# PIC32MX274F256B device description
Architecture: MIPS; Family: PIC32MX; Series: PIC32MX
Registers are 32-bit, read-write, no defined reset value unless marked. A register's access mark holds for its fields unless they carry their own. Offsets are from the block's base; [hi:lo] are bit positions; {n}, {i} and the like mark numbered series; 'fields as' and 'values as' point back to an identical list.

## ADC
Instances: ADC 0x1f809000 in periph0
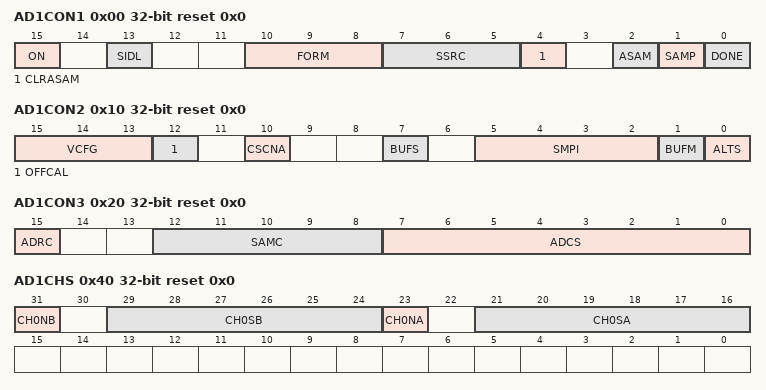
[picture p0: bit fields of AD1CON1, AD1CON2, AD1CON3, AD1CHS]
0x00 AD1CON1 reset 0x0 — ADC Control Register 1
  [15] ON — ADC Operating Mode bit
    1=ADC module is operating; 0=ADC module is not operating
  [13] SIDL — Stop in Idle Mode bit
    1=Discontinue module operation when device enters Idle mode; 0=Continue module operation in Idle mode
  [10:8] FORM — Data Output Format bits
    3=Signed Fractional 16-bit; 2=Fractional 16-bit; 1=Signed Integer 16-bit; 0=Integer 16-bit; 7=Signed Fractional 32-bit; 6=Fractional 32-bit; 5=Signed Integer 32-bit; 4=Integer 32-bit
  [7:5] SSRC — Conversion Trigger Source Select bits
    7=Internal counter ends sampling and starts conversion (auto convert); 3=CTMU ends sampling and starts conversion; 2=Timer 3 period match ends sampling and starts conversion; 1=Active transition on INT0 pin ends sampling and starts conversion; 0=Clearing SAMP bit ends sampling and starts conversion
  [4] CLRASAM — Stop Conversion Sequence bit (when the first ADC interrupt is generated)
    1=Stop conversions when the first ADC interrupt is generated. Hardware clears the ASAM bit when the ADC interrupt is generated; 0=Normal operation, buffer contents will be overwritten by the next conversion sequence
  [2] ASAM — ADC Sample Auto-Start bit
    1=Sampling begins immediately after last conversion completes; SAMP bit is automatically set; 0=Sampling begins when SAMP bit is set
  [1] SAMP — ADC Sample Enable bit
    1=The ADC sample and hold amplifier is sampling; 0=The ADC sample/hold amplifier is holding
  [0] DONE — Analog-to-Digital Conversion Status bit
    1=Analog-to-digital conversion is done; 0=Analog-to-digital conversion is not done or has not started
0x10 AD1CON2 reset 0x0 — ADC Control Register 2
  [15:13] VCFG — Voltage Reference Configuration bits
    0=VREFH is AVDD and VREFL is AVSS; 1=VREFH is External VREF+ pin and VREFL is AVSS; 2=VREFH is AVDD and VREFL is External VREF- pin; 3=VREFH is External VREF+ pin and VREFL is External VREF- pin; {v}=VREFH is AVDD and VREFL is AVSS (v=4..7)
  [12] OFFCAL — Input Offset Calibration Mode Select bit
    1=Enable Offset Calibration mode; 0=Disable Offset Calibration mode
  [10] CSCNA — Input Scan Select bit
    1=Scan inputs; 0=Do not scan inputs
  [7] BUFS — Buffer Fill Status bit
    1=ADC is currently filling buffer 0x8-0xF, user should access data in 0x0-0x7; 0=ADC is currently filling buffer 0x0-0x7, user should access data in 0x8-0xF
  [5:2] SMPI — Sample/Convert Sequences Per Interrupt Selection bits
    {v}=Interrupts at the completion of conversion for each {v+1}th sample/convert sequence (v=3..15); 2=Interrupts at the completion of conversion for each 3rd sample/convert sequence; 1=Interrupts at the completion of conversion for each 2nd sample/convert sequence; 0=Interrupts at the completion of conversion for each sample/convert sequence
  [1] BUFM — ADC Result Buffer Mode Select bit
    1=Buffer configured as two 8-word buffers; 0=Buffer configured as one 16-word buffer ADC1BUFF-ADC1BUF0
  [0] ALTS — Alternate Input Sample Mode Select bit
    1=Uses Sample A input multiplexer settings for first sample then alternates between Sample B and Sample A input multiplexer settings for all subsequent samples; 0=Always use Sample A input multiplexer settings
0x20 AD1CON3 reset 0x0 — ADC Control Register 3
  [15] ADRC — ADC Conversion Clock Source bit
    1=Clock derived from FRC; 0=Clock derived from Peripheral Bus Clock (PBCLK)
  [12:8] SAMC — Auto-Sample Time bits
    {v}={v} TAD (v=1..31)
  [7:0] ADCS — ADC Conversion Clock Select bits
    255=512 TPB; 254=510 TPB; 253=508 TPB; 252=506 TPB; 251=504 TPB; 250=502 TPB; 249=500 TPB; 248=498 TPB; 247=496 TPB; 246=494 TPB; 245=492 TPB; 244=490 TPB; 243=488 TPB; 242=486 TPB; 241=484 TPB; 240=482 TPB; 239=480 TPB; 238=478 TPB; 237=476 TPB; 236=474 TPB; 235=472 TPB; 234=470 TPB; 233=468 TPB; 232=466 TPB; 231=464 TPB; 230=462 TPB; 229=460 TPB; 228=458 TPB; 227=456 TPB; 226=454 TPB; 225=452 TPB; 224=450 TPB; 223=448 TPB; 222=446 TPB; 221=444 TPB; 220=442 TPB; 219=440 TPB; 218=438 TPB; 217=436 TPB; 216=434 TPB; 215=432 TPB; 214=430 TPB; 213=428 TPB; 212=426 TPB; 211=424 TPB; 210=422 TPB; 209=420 TPB; 208=418 TPB; 207=416 TPB; 206=414 TPB; 205=412 TPB; 204=410 TPB; 203=408 TPB; 202=406 TPB; 201=404 TPB; 200=402 TPB; 199=400 TPB; 198=398 TPB; 197=396 TPB; 196=394 TPB; 195=392 TPB; 194=390 TPB; 193=388 TPB; 192=386 TPB; 191=384 TPB; 190=382 TPB; 189=380 TPB; 188=378 TPB; 187=376 TPB; 186=374 TPB; 185=372 TPB; 184=370 TPB; 183=368 TPB; 182=366 TPB; 181=364 TPB; 180=362 TPB; 179=360 TPB; 178=358 TPB; 177=356 TPB; 176=354 TPB; 175=352 TPB; 174=350 TPB; 173=348 TPB; 172=346 TPB; 171=344 TPB; 170=342 TPB; 169=340 TPB; 168=338 TPB; 167=336 TPB; 166=334 TPB; 165=332 TPB; 164=330 TPB; 163=328 TPB; 162=326 TPB; 161=324 TPB; 160=322 TPB; 159=320 TPB; 158=318 TPB; 157=316 TPB; 156=314 TPB; 155=312 TPB; 154=310 TPB; 153=308 TPB; 152=306 TPB; 151=304 TPB; 150=302 TPB; 149=300 TPB; 148=298 TPB; 147=296 TPB; 146=294 TPB; 145=292 TPB; 144=290 TPB; 143=288 TPB; 142=286 TPB; 141=284 TPB; 140=282 TPB; 139=280 TPB; 138=278 TPB; 137=276 TPB; 136=274 TPB; 135=272 TPB; 134=270 TPB; 133=268 TPB; 132=266 TPB; 131=264 TPB; 130=262 TPB; 129=260 TPB; 128=258 TPB; 127=256 TPB; 126=254 TPB; 125=252 TPB; 124=250 TPB; 123=248 TPB; 122=246 TPB; 121=244 TPB; 120=242 TPB; 119=240 TPB; 118=238 TPB; 117=236 TPB; 116=234 TPB; 115=232 TPB; 114=230 TPB; 113=228 TPB; 112=226 TPB; 111=224 TPB; 110=222 TPB; 109=220 TPB; 108=218 TPB; 107=216 TPB; 106=214 TPB; 105=212 TPB; 104=210 TPB; 103=208 TPB; 102=206 TPB; 101=204 TPB; 100=202 TPB; 99=200 TPB; 98=198 TPB; 97=196 TPB; 96=194 TPB; 95=192 TPB; 94=190 TPB; 93=188 TPB; 92=186 TPB; 91=184 TPB; 90=182 TPB; 89=180 TPB; 88=178 TPB; 87=176 TPB; 86=174 TPB; 85=172 TPB; 84=170 TPB; 83=168 TPB; 82=166 TPB; 81=164 TPB; 80=162 TPB; 79=160 TPB; 78=158 TPB; 77=156 TPB; 76=154 TPB; 75=152 TPB; 74=150 TPB; 73=148 TPB; 72=146 TPB; 71=144 TPB; 70=142 TPB; 69=140 TPB; 68=138 TPB; 67=136 TPB; 66=134 TPB; 65=132 TPB; 64=130 TPB; 63=128 TPB; 62=126 TPB; 61=124 TPB; 60=122 TPB; 59=120 TPB; 58=118 TPB; 57=116 TPB; 56=114 TPB; 55=112 TPB; 54=110 TPB; 53=108 TPB; 52=106 TPB; 51=104 TPB; 50=102 TPB; 49=100 TPB; 48=98 TPB; 47=96 TPB; 46=94 TPB; 45=92 TPB; 44=90 TPB; 43=88 TPB; 42=86 TPB; 41=84 TPB; 40=82 TPB; 39=80 TPB; 38=78 TPB; 37=76 TPB; 36=74 TPB; 35=72 TPB; 34=70 TPB; 33=68 TPB; 32=66 TPB; 31=64 TPB; 30=62 TPB; 29=60 TPB; 28=58 TPB; 27=56 TPB; 26=54 TPB; 25=52 TPB; 24=50 TPB; 23=48 TPB; 22=46 TPB; 21=44 TPB; 20=42 TPB; 19=40 TPB; 18=38 TPB; 17=36 TPB; 16=34 TPB; 15=32 TPB; 14=30 TPB; 13=28 TPB; 12=26 TPB; 11=24 TPB; 10=22 TPB; 9=20 TPB; 8=18 TPB; 7=16 TPB; 6=14 TPB; 5=12 TPB; 4=10 TPB; 3=8 TPB; 2=6 TPB; 1=4 TPB; 0=2 TPB
0x40 AD1CHS reset 0x0 — ADC Input Select Register
  [31] CH0NB — Negative Input Select bit for Sample B
    1=Channel 0 negative input is AN1; 0=Channel 0 negative input is VREFL
  [29:24] CH0SB — Positive Input Select bits for Sample B
    17=VDD_DIV_2 (Channel 0 positive input is VDD/2); 14=IVREF (Channel 0 positive input is IVREF); 13=CTMUT (Channel 0 positive input is CTMU temperature sensor (CTMUT)); 11=AN11 (Channel 0 positive input is AN11); 10=AN10 (Channel 0 positive input is AN10); 9=AN9 (Channel 0 positive input is AN9); {v}=AN{v} (Channel 0 positive input is AN{v}) (v=0..5)
  [23] CH0NA — Negative Input Select bit for Sample A Multiplexer Setting
    1=AN1 (Channel 0 negative input is AN1); 0=VREFL (Channel 0 negative input is VREFL)
  [21:16] CH0SA — Positive Input Select bits for Sample A Multiplexer Setting
    values as CH0SB
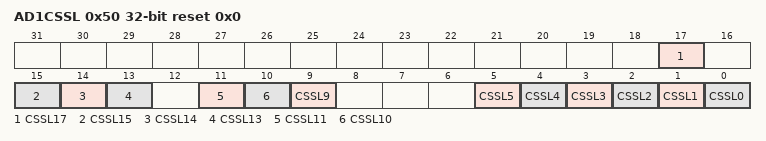
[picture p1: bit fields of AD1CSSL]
0x50 AD1CSSL reset 0x0 — ADC Input Scan Select Register
  [17] CSSL17 — ADC Input Pin Scan Selection bits
    1=Select VDD_DIV_2 for input scan; CSSL17 = VDD_DIV_2; 0=Skip VDD_DIV_2 for input scan; CSSL17 = VDD_DIV_2
  [15] CSSL15 — ADC Input Pin Scan Selection bits
    1=Select AVSS for input scan; CSSL15 = AVSS; 0=Skip AVSS for input scan; CSSL15 = AVSS
  [14] CSSL14 — ADC Input Pin Scan Selection bits
    1=Select IVREF for input scan; CSSL14 = IVREF; 0=Skip IVREF for input scan; CSSL14 = IVREF
  [13] CSSL13 — ADC Input Pin Scan Selection bits
    1=Select CTMUT for input scan; CSSL13 = CTMUT; 0=Skip CTMUT for input scan; CSSL13 = CTMUT
  [11] CSSL11 — ADC Input Pin Scan Selection bits
    1=Select AN11 for input scan; CSSL11 = AN11; 0=Skip AN11 for input scan; CSSL11 = AN11
  [10] CSSL10 — ADC Input Pin Scan Selection bits
    1=Select AN10 for input scan; CSSL10 = AN10; 0=Skip AN10 for input scan; CSSL10 = AN10
  [9] CSSL9 — ADC Input Pin Scan Selection bits
    1=Select AN9 for input scan; CSSL9 = AN9; 0=Skip AN9 for input scan; CSSL9 = AN9
  [n] CSSL{n} (n=0..5) — ADC Input Pin Scan Selection bits
    1=Select AN{n} for input scan; CSSL{n} = AN{n}; 0=Skip AN{n} for input scan; CSSL{n} = AN{n}
{0x70+0x10*i} ADC1BUF{i} ro (i=0..9)
0x110 ADC1BUFA ro
0x120 ADC1BUFB ro
0x130 ADC1BUFC ro
0x140 ADC1BUFD ro
0x150 ADC1BUFE ro
0x160 ADC1BUFF ro

## Notices in the file
Copyright (c) 2019 Microchip Technology Inc.
SPDX-License-Identifier: Apache-2.0
Licensed under the Apache License, Version 2.0 (the "License");
you may not use this file except in compliance with the License.
You may obtain a copy of the License at
http://www.apache.org/licenses/LICENSE-2.0
Unless required by applicable law or agreed to in writing, software
distributed under the License is distributed on an "AS IS" BASIS,
WITHOUT WARRANTIES OR CONDITIONS OF ANY KIND, either express or implied.
See the License for the specific language governing permissions and
limitations under the License.
